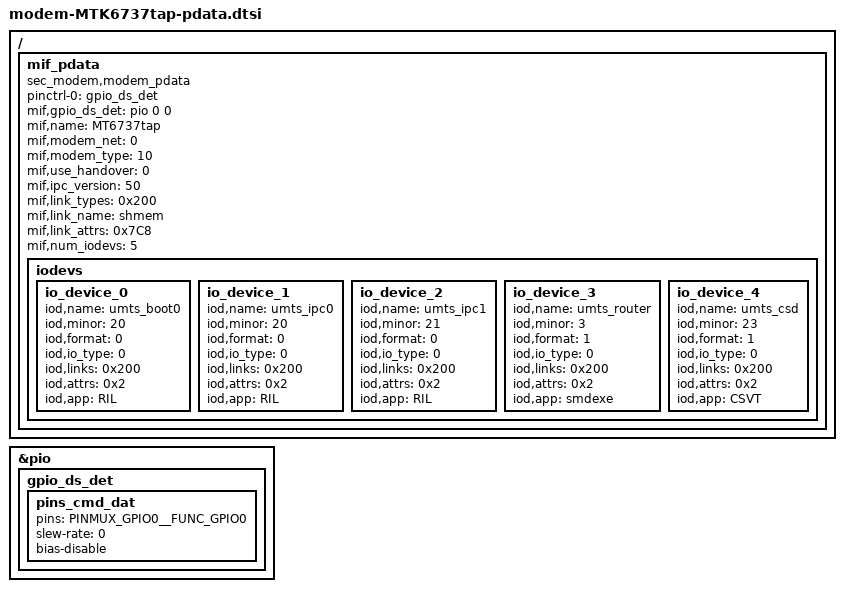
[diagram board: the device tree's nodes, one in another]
/*
 * MEDIATEK MT6755 board device tree source
 *
 * Copyright (c) 2016 Samsung Electronics Co., Ltd.
 *             http://www.samsung.com
 *
 * This program is free software; you can redistribute it and/or modify
 * it under the terms of the GNU General Public License version 2 as
 * published by the Free Software Foundation.
*/

/ {
	/* modem_interface_driver: MT6737t */
	mif_pdata {
		compatible = "sec_modem,modem_pdata";
		status = "okay";

		pinctrl-names = "default";
		pinctrl-0 = <&gpio_ds_det>;

		mif,gpio_ds_det = <&pio 0 0>;

		/* common pdata */
		mif,name = "MT6737tap";
		mif,modem_net = <0>;		/* UMTS_NETWORK */
		mif,modem_type = <10>;		/* SEC_SS310AP */
		mif,use_handover = <0>;		/* not used */
		mif,ipc_version = <50>;		/* SIPC 5.0 */
		mif,link_types = <0x200>;	/* LINKDEV_SHMEM */
		mif,link_name = "shmem";
		mif,link_attrs = <0x7C8>;	/* XMIT_BTDLR(0x400) | DUMP_ALIGNED (0x200) | BOOT_ALIGNED (0x100) | MEM_DUMP (0x80) | MEM_BOOT (0x40) | DPRAM_MAGIC (0x08) */
		mif,num_iodevs = <5>;
	
		iodevs {
			io_device_0 {
				iod,name = "umts_boot0";
				iod,minor = <20>;
				iod,format = <0>;		/* IPC_FMT */
				iod,io_type = <0>;		/* IODEV_MISC */
				iod,links = <0x200>;		/* LINKDEV_SHMEM */
				iod,attrs = <0x2>;		/* ATTR_SIPC5 */
				iod,app = "RIL";
			};
			io_device_1 {
				iod,name = "umts_ipc0";
				iod,minor = <20>;
				iod,format = <0>;		/* IPC_FMT */
				iod,io_type = <0>;		/* IODEV_MISC */
				iod,links = <0x200>;		/* LINKDEV_SHMEM */
				iod,attrs = <0x2>;		/* ATTR_SIPC5 */
				iod,app = "RIL";
			};
			io_device_2 {
				iod,name = "umts_ipc1";
				iod,minor = <21>;
				iod,format = <0>;		/* IPC_FMT */
				iod,io_type = <0>;		/* IODEV_MISC */
				iod,links = <0x200>;		/* LINKDEV_SHMEM */
				iod,attrs = <0x2>;		/* ATTR_SIPC5 */
				iod,app = "RIL";
			};
			io_device_3 {
				iod,name = "umts_router";
				iod,minor = <3>;
				iod,format = <1>;		/* IPC_FMT */
				iod,io_type = <0>;		/* IODEV_MISC */
				iod,links = <0x200>;		/* LINKDEV_SHMEM */
				iod,attrs = <0x2>;		/* ATTR_SIPC5 */
				iod,app = "smdexe";
			};
			io_device_4 {
				iod,name = "umts_csd";
				iod,minor = <23>;
				iod,format = <1>;		/* IPC_FMT */
				iod,io_type = <0>;		/* IODEV_MISC */
				iod,links = <0x200>;		/* LINKDEV_SHMEM */
				iod,attrs = <0x2>;		/* ATTR_SIPC5 */
				iod,app = "CSVT";
			};
		}; /* end of iodevs */

	}; /* end of mif_pdata */

};

&pio {
	gpio_ds_det: gpio_ds_det {
		pins_cmd_dat {
			pins = <PINMUX_GPIO0__FUNC_GPIO0>;
			slew-rate = <0>;
			bias-disable;
		};
	};
};
